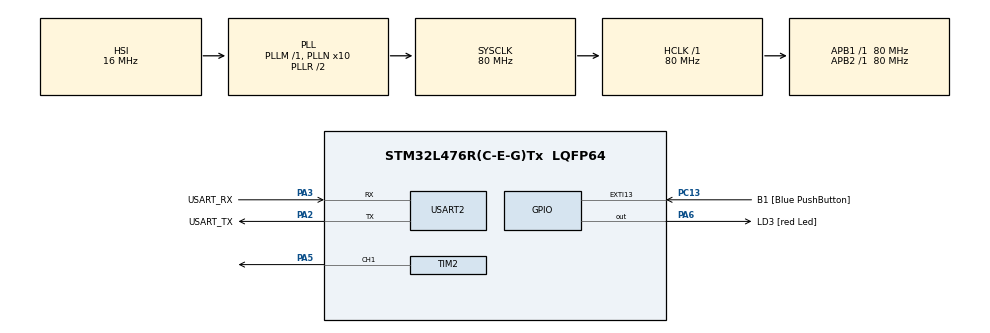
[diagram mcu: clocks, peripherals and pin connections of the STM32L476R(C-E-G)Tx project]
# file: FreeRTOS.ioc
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FREERTOS.Queues01=myQueue01,5,uint16_t,0,Dynamic,NULL,NULL
FREERTOS.Tasks01=defaultTask,24,128,StartDefaultTask,Default,NULL,Dynamic,NULL,NULL;BlueLedBlink,24,128,entry_BlueLedBlink,As weak,&blueLed,Dynamic,NULL,NULL;UART,8,256,entry_UART,As weak,NULL,Dynamic,NULL,NULL;RedLedBlink,24,128,entry_RedLedBlink,As weak,&redLed,Dynamic,NULL,NULL;BlueLedBrightne,24,128,entry_BlueLedBrightness,As weak,NULL,Dynamic,NULL,NULL
FREERTOS.configTOTAL_HEAP_SIZE=5000
Mcu.Family=STM32L4
Mcu.Name=STM32L476R(C-E-G)Tx
Mcu.Package=LQFP64
NVIC.PriorityGroup=NVIC_PRIORITYGROUP_4
NVIC.TIM1_UP_TIM16_IRQn=true\:15\:0\:false\:false\:true\:false\:false\:true\:true
NVIC.TimeBase=TIM1_UP_TIM16_IRQn
NVIC.TimeBaseIP=TIM16
PA13\ (JTMS-SWDIO).GPIO_Label=TMS
PA13\ (JTMS-SWDIO).Mode=Serial_Wire
PA13\ (JTMS-SWDIO).Signal=SYS_JTMS-SWDIO
PA14\ (JTCK-SWCLK).GPIO_Label=TCK
PA14\ (JTCK-SWCLK).Mode=Serial_Wire
PA14\ (JTCK-SWCLK).Signal=SYS_JTCK-SWCLK
PA2.GPIO_Label=USART_TX
PA2.GPIO_Mode=GPIO_MODE_AF_PP
PA2.GPIO_PuPd=GPIO_NOPULL
PA2.GPIO_Speed=GPIO_SPEED_FREQ_VERY_HIGH
PA2.Mode=Asynchronous
PA2.Signal=USART2_TX
PA3.GPIO_Label=USART_RX
PA3.GPIO_Mode=GPIO_MODE_AF_PP
PA3.GPIO_PuPd=GPIO_NOPULL
PA3.GPIO_Speed=GPIO_SPEED_FREQ_VERY_HIGH
PA3.Mode=Asynchronous
PA3.Signal=USART2_RX
PA5.Signal=S_TIM2_CH1
PA6.GPIO_Label=LD3 [red Led]
PA6.Signal=GPIO_Output
PB3\ (JTDO-TRACESWO).GPIO_Label=SWO
PB3\ (JTDO-TRACESWO).Signal=SYS_JTDO-SWO
PC13.GPIO_Label=B1 [Blue PushButton]
PC13.GPIO_ModeDefaultEXTI=GPIO_MODE_IT_FALLING
PC13.GPIO_PuPd=GPIO_NOPULL
PC13.Signal=GPXTI13
PC14-OSC32_IN\ (PC14).Mode=LSE-External-Oscillator
PC14-OSC32_IN\ (PC14).Signal=RCC_OSC32_IN
PC15-OSC32_OUT\ (PC15).Mode=LSE-External-Oscillator
PC15-OSC32_OUT\ (PC15).Signal=RCC_OSC32_OUT
PH0-OSC_IN\ (PH0).Signal=RCC_OSC_IN
PH1-OSC_OUT\ (PH1).Signal=RCC_OSC_OUT
ProjectManager.HeapSize=0x200
ProjectManager.StackSize=0x400
ProjectManager.TargetToolchain=STM32CubeIDE
RCC.ADCFreq_Value=64000000
RCC.AHBFreq_Value=80000000
RCC.APB1Freq_Value=80000000
RCC.APB1TimFreq_Value=80000000
RCC.APB2Freq_Value=80000000
RCC.APB2TimFreq_Value=80000000
RCC.CortexFreq_Value=80000000
RCC.HCLKFreq_Value=80000000
RCC.HSE_VALUE=8000000
RCC.HSI_VALUE=16000000
RCC.MSI_VALUE=4000000
RCC.PLLN=10
RCC.PLLSourceVirtual=RCC_PLLSOURCE_HSI
RCC.PREFETCH_ENABLE=1
RCC.SYSCLKFreq_VALUE=80000000
RCC.SYSCLKSource=RCC_SYSCLKSOURCE_PLLCLK
RCC.USBFreq_Value=64000000
RCC.VCOOutputFreq_Value=160000000
SH.S_TIM2_CH1.0=TIM2_CH1,PWM Generation1 CH1
TIM2.Channel-PWM\ Generation1\ CH1=TIM_CHANNEL_1
TIM2.Period=100
TIM2.Prescaler=7999
TIM2.Pulse-PWM\ Generation1\ CH1=30
USART2.VirtualMode-Asynchronous=VM_ASYNC
VP_FREERTOS_VS_CMSIS_V2.Mode=CMSIS_V2
VP_SYS_VS_tim16.Mode=TIM16
VP_TIM2_VS_ClockSourceINT.Mode=Internal
board=NUCLEO-L476RG

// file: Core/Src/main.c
/* USER CODE BEGIN Header */
/**
  ******************************************************************************
  * @file           : main.c
  * @brief          : Main program body
  ******************************************************************************
  * @attention
  *
  * Copyright (c) 2022 STMicroelectronics.
  * All rights reserved.
  *
  * This software is licensed under terms that can be found in the LICENSE file
  * in the root directory of this software component.
  * If no LICENSE file comes with this software, it is provided AS-IS.
  *
  ******************************************************************************
  */
/* USER CODE END Header */
#include "main.h"
#include "cmsis_os.h"

/* USER CODE BEGIN Includes */
#include "Led.h"
#include "Communication.h"
/* USER CODE END Includes */

 TIM_HandleTypeDef htim2;

UART_HandleTypeDef huart2;

/* Definitions for defaultTask */
osThreadId_t defaultTaskHandle;
const osThreadAttr_t defaultTask_attributes = {
  .name = "defaultTask",
  .stack_size = 128 * 4,
  .priority = (osPriority_t) osPriorityNormal,
};
/* Definitions for BlueLedBlink */
osThreadId_t BlueLedBlinkHandle;
const osThreadAttr_t BlueLedBlink_attributes = {
  .name = "BlueLedBlink",
  .stack_size = 128 * 4,
  .priority = (osPriority_t) osPriorityNormal,
};
/* Definitions for UART */
osThreadId_t UARTHandle;
const osThreadAttr_t UART_attributes = {
  .name = "UART",
  .stack_size = 256 * 4,
  .priority = (osPriority_t) osPriorityLow,
};
/* Definitions for RedLedBlink */
osThreadId_t RedLedBlinkHandle;
const osThreadAttr_t RedLedBlink_attributes = {
  .name = "RedLedBlink",
  .stack_size = 128 * 4,
  .priority = (osPriority_t) osPriorityNormal,
};
/* Definitions for BlueLedBrightne */
osThreadId_t BlueLedBrightneHandle;
const osThreadAttr_t BlueLedBrightne_attributes = {
  .name = "BlueLedBrightne",
  .stack_size = 128 * 4,
  .priority = (osPriority_t) osPriorityNormal,
};
/* Definitions for myQueue01 */
osMessageQueueId_t myQueue01Handle;
const osMessageQueueAttr_t myQueue01_attributes = {
  .name = "myQueue01"
};
/* USER CODE BEGIN PV */
int _write(int fd, char* ptr, int len)
{
	HAL_UART_Transmit(&huart2, (uint8_t*)ptr, len, HAL_MAX_DELAY);
	return len;
}
/* USER CODE END PV */

void SystemClock_Config(void);
static void MX_GPIO_Init(void);
static void MX_USART2_UART_Init(void);
static void MX_TIM2_Init(void);
void StartDefaultTask(void *argument);
void entry_BlueLedBlink(void *argument);
void entry_UART(void *argument);
void entry_RedLedBlink(void *argument);
void entry_BlueLedBrightness(void *argument);

/* USER CODE BEGIN 0 */

Led blueLed;
Led redLed;

/* USER CODE END 0 */

int main(void)
{

  /* MCU Configuration--------------------------------------------------------*/

  /* Reset of all peripherals, Initializes the Flash interface and the Systick. */
  HAL_Init();

  /* Configure the system clock */
  SystemClock_Config();

  /* Initialize all configured peripherals */
  MX_GPIO_Init();
  MX_USART2_UART_Init();
  MX_TIM2_Init();
  /* USER CODE BEGIN 2 */

  // when the led work on PWM it can work on GPIO
  //Led_init(&blueLed,LD2_GPIO_Port, LD2_Pin);
  //Led_init(&redLed,LD3_GPIO_Port, LD3_Pin);

  /* USER CODE END 2 */

  /* Init scheduler */
  osKernelInitialize();

  /* Create the queue(s) */
  /* creation of myQueue01 */
  myQueue01Handle = osMessageQueueNew (5, sizeof(uint16_t), &myQueue01_attributes);

  /* Create the thread(s) */
  /* creation of defaultTask */
  defaultTaskHandle = osThreadNew(StartDefaultTask, NULL, &defaultTask_attributes);

  /* creation of BlueLedBlink */
  BlueLedBlinkHandle = osThreadNew(entry_BlueLedBlink, (void*) &blueLed, &BlueLedBlink_attributes);

  /* creation of UART */
  UARTHandle = osThreadNew(entry_UART, NULL, &UART_attributes);

  /* creation of RedLedBlink */
//  RedLedBlinkHandle = osThreadNew(entry_RedLedBlink, (void*) &redLed, &RedLedBlink_attributes);

  /* creation of BlueLedBrightne */
//  BlueLedBrightneHandle = osThreadNew(entry_BlueLedBrightness, NULL, &BlueLedBrightne_attributes);

  /* Start scheduler */
  osKernelStart();

  /* We should never get here as control is now taken by the scheduler */
  /* Infinite loop */
  while (1)
  {

  }
}

void SystemClock_Config(void)
{
  RCC_OscInitTypeDef RCC_OscInitStruct = {0};
  RCC_ClkInitTypeDef RCC_ClkInitStruct = {0};

  /** Configure the main internal regulator output voltage
  */
  if (HAL_PWREx_ControlVoltageScaling(PWR_REGULATOR_VOLTAGE_SCALE1) != HAL_OK)
  {
    Error_Handler();
  }

  /** Initializes the RCC Oscillators according to the specified parameters
  * in the RCC_OscInitTypeDef structure.
  */
  RCC_OscInitStruct.OscillatorType = RCC_OSCILLATORTYPE_HSI;
  RCC_OscInitStruct.HSIState = RCC_HSI_ON;
  RCC_OscInitStruct.HSICalibrationValue = RCC_HSICALIBRATION_DEFAULT;
  RCC_OscInitStruct.PLL.PLLState = RCC_PLL_ON;
  RCC_OscInitStruct.PLL.PLLSource = RCC_PLLSOURCE_HSI;
  RCC_OscInitStruct.PLL.PLLM = 1;
  RCC_OscInitStruct.PLL.PLLN = 10;
  RCC_OscInitStruct.PLL.PLLP = RCC_PLLP_DIV7;
  RCC_OscInitStruct.PLL.PLLQ = RCC_PLLQ_DIV2;
  RCC_OscInitStruct.PLL.PLLR = RCC_PLLR_DIV2;
  if (HAL_RCC_OscConfig(&RCC_OscInitStruct) != HAL_OK)
  {
    Error_Handler();
  }

  /** Initializes the CPU, AHB and APB buses clocks
  */
  RCC_ClkInitStruct.ClockType = RCC_CLOCKTYPE_HCLK|RCC_CLOCKTYPE_SYSCLK
                              |RCC_CLOCKTYPE_PCLK1|RCC_CLOCKTYPE_PCLK2;
  RCC_ClkInitStruct.SYSCLKSource = RCC_SYSCLKSOURCE_PLLCLK;
  RCC_ClkInitStruct.AHBCLKDivider = RCC_SYSCLK_DIV1;
  RCC_ClkInitStruct.APB1CLKDivider = RCC_HCLK_DIV1;
  RCC_ClkInitStruct.APB2CLKDivider = RCC_HCLK_DIV1;

  if (HAL_RCC_ClockConfig(&RCC_ClkInitStruct, FLASH_LATENCY_4) != HAL_OK)
  {
    Error_Handler();
  }
}

static void MX_TIM2_Init(void)
{

  TIM_ClockConfigTypeDef sClockSourceConfig = {0};
  TIM_MasterConfigTypeDef sMasterConfig = {0};
  TIM_OC_InitTypeDef sConfigOC = {0};

  htim2.Instance = TIM2;
  htim2.Init.Prescaler = 7999;
  htim2.Init.CounterMode = TIM_COUNTERMODE_UP;
  htim2.Init.Period = 100;
  htim2.Init.ClockDivision = TIM_CLOCKDIVISION_DIV1;
  htim2.Init.AutoReloadPreload = TIM_AUTORELOAD_PRELOAD_DISABLE;
  if (HAL_TIM_Base_Init(&htim2) != HAL_OK)
  {
    Error_Handler();
  }
  sClockSourceConfig.ClockSource = TIM_CLOCKSOURCE_INTERNAL;
  if (HAL_TIM_ConfigClockSource(&htim2, &sClockSourceConfig) != HAL_OK)
  {
    Error_Handler();
  }
  if (HAL_TIM_PWM_Init(&htim2) != HAL_OK)
  {
    Error_Handler();
  }
  sMasterConfig.MasterOutputTrigger = TIM_TRGO_RESET;
  sMasterConfig.MasterSlaveMode = TIM_MASTERSLAVEMODE_DISABLE;
  if (HAL_TIMEx_MasterConfigSynchronization(&htim2, &sMasterConfig) != HAL_OK)
  {
    Error_Handler();
  }
  sConfigOC.OCMode = TIM_OCMODE_PWM1;
  sConfigOC.Pulse = 30;
  sConfigOC.OCPolarity = TIM_OCPOLARITY_HIGH;
  sConfigOC.OCFastMode = TIM_OCFAST_DISABLE;
  if (HAL_TIM_PWM_ConfigChannel(&htim2, &sConfigOC, TIM_CHANNEL_1) != HAL_OK)
  {
    Error_Handler();
  }
  HAL_TIM_MspPostInit(&htim2);

}

static void MX_USART2_UART_Init(void)
{

  huart2.Instance = USART2;
  huart2.Init.BaudRate = 115200;
  huart2.Init.WordLength = UART_WORDLENGTH_8B;
  huart2.Init.StopBits = UART_STOPBITS_1;
  huart2.Init.Parity = UART_PARITY_NONE;
  huart2.Init.Mode = UART_MODE_TX_RX;
  huart2.Init.HwFlowCtl = UART_HWCONTROL_NONE;
  huart2.Init.OverSampling = UART_OVERSAMPLING_16;
  huart2.Init.OneBitSampling = UART_ONE_BIT_SAMPLE_DISABLE;
  huart2.AdvancedInit.AdvFeatureInit = UART_ADVFEATURE_NO_INIT;
  if (HAL_UART_Init(&huart2) != HAL_OK)
  {
    Error_Handler();
  }

}

static void MX_GPIO_Init(void)
{
  GPIO_InitTypeDef GPIO_InitStruct = {0};

  /* GPIO Ports Clock Enable */
  __HAL_RCC_GPIOC_CLK_ENABLE();
  __HAL_RCC_GPIOH_CLK_ENABLE();
  __HAL_RCC_GPIOA_CLK_ENABLE();
  __HAL_RCC_GPIOB_CLK_ENABLE();

  /*Configure GPIO pin Output Level */
  HAL_GPIO_WritePin(LD3_GPIO_Port, LD3_Pin, GPIO_PIN_RESET);

  /*Configure GPIO pin : B1_Pin */
  GPIO_InitStruct.Pin = B1_Pin;
  GPIO_InitStruct.Mode = GPIO_MODE_IT_FALLING;
  GPIO_InitStruct.Pull = GPIO_NOPULL;
  HAL_GPIO_Init(B1_GPIO_Port, &GPIO_InitStruct);

  /*Configure GPIO pin : LD3_Pin */
  GPIO_InitStruct.Pin = LD3_Pin;
  GPIO_InitStruct.Mode = GPIO_MODE_OUTPUT_PP;
  GPIO_InitStruct.Pull = GPIO_NOPULL;
  GPIO_InitStruct.Speed = GPIO_SPEED_FREQ_LOW;
  HAL_GPIO_Init(LD3_GPIO_Port, &GPIO_InitStruct);

}

void StartDefaultTask(void *argument)
{
  for(;;)
  {
    osDelay(1);
  }
}

__weak void entry_BlueLedBlink(void *argument)
{
  for(;;)
  {
    osDelay(1);
  }
}

__weak void entry_UART(void *argument)
{
  for(;;)
  {
    osDelay(1);
  }
}

__weak void entry_RedLedBlink(void *argument)
{
  for(;;)
  {
    osDelay(1);
  }
}

__weak void entry_BlueLedBrightness(void *argument)
{
  for(;;)
  {
    osDelay(1);
  }
}

void HAL_TIM_PeriodElapsedCallback(TIM_HandleTypeDef *htim)
{
  if (htim->Instance == TIM16) {
    HAL_IncTick();
  }
}

void Error_Handler(void)
{
  __disable_irq();
  while (1)
  {
  }
}
